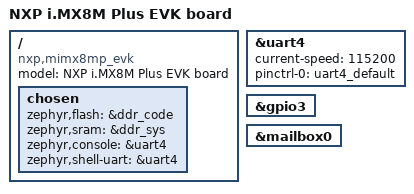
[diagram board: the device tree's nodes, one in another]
/*
 * Copyright (c) 2021, Laird Connectivity
 *
 * SPDX-License-Identifier: Apache-2.0
 */

/dts-v1/;

#include <nxp/nxp_imx8ml_m7.dtsi>
#include "imx8mp_evk-pinctrl.dtsi"

/ {
	model = "NXP i.MX8M Plus EVK board";
	compatible = "nxp,mimx8mp_evk";

	chosen {
		/* DDR */
		zephyr,flash = &ddr_code;
		zephyr,sram = &ddr_sys;

		zephyr,console = &uart4;
		zephyr,shell-uart = &uart4;
	};
};

&uart4 {
	status = "okay";
	current-speed = <115200>;
	pinctrl-0 = <&uart4_default>;
	pinctrl-names = "default";
};

&gpio3 {
	status = "okay";
};

&mailbox0 {
	status = "okay";
};
